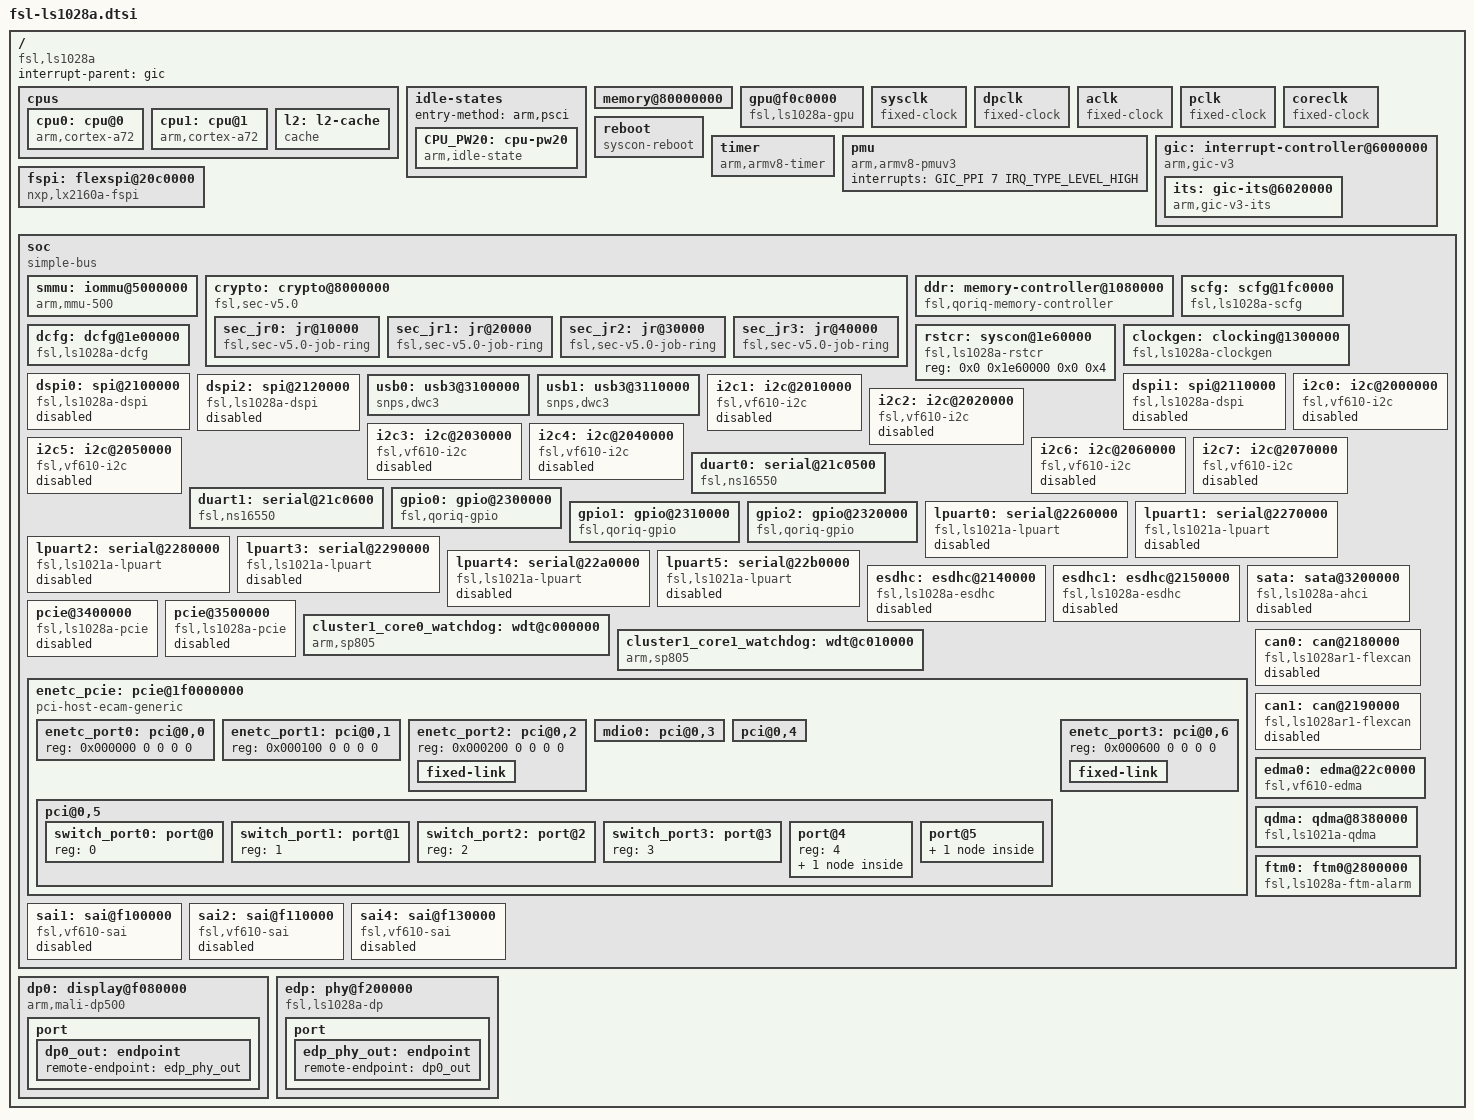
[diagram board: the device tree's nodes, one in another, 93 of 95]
// SPDX-License-Identifier: (GPL-2.0+ OR MIT)
/*
 * Device Tree Include file for NXP Layerscape-1028A family SoC.
 *
 * Copyright 2017-2019 NXP
 *
 * Harninder Rai <harninder.rai@nxp.com>
 *
 */

#include <dt-bindings/interrupt-controller/arm-gic.h>
#include <dt-bindings/thermal/thermal.h>

/ {
	compatible = "fsl,ls1028a";
	interrupt-parent = <&gic>;
	#address-cells = <2>;
	#size-cells = <2>;

	cpus {
		#address-cells = <1>;
		#size-cells = <0>;

		cpu0: cpu@0 {
			device_type = "cpu";
			compatible = "arm,cortex-a72";
			reg = <0x0>;
			clocks = <&clockgen 1 0>;
			next-level-cache = <&l2>;
			cpu-idle-states = <&CPU_PW20>;
			#cooling-cells = <2>;
		};

		cpu1: cpu@1 {
			device_type = "cpu";
			compatible = "arm,cortex-a72";
			reg = <0x1>;
			clocks = <&clockgen 1 0>;
			next-level-cache = <&l2>;
			cpu-idle-states = <&CPU_PW20>;
		};

		l2: l2-cache {
			compatible = "cache";
		};
	};

	idle-states {
		/*
		 * PSCI node is not added default, U-boot will add missing
		 * parts if it determines to use PSCI.
		 */
		entry-method = "arm,psci";

		CPU_PW20: cpu-pw20 {
			  compatible = "arm,idle-state";
			  idle-state-name = "PW20";
			  arm,psci-suspend-param = <0x0>;
			  entry-latency-us = <2000>;
			  exit-latency-us = <2000>;
			  min-residency-us = <6000>;
		};
	};

	memory@80000000 {
		device_type = "memory";
	};

	gpu@f0c0000 {
		compatible = "fsl,ls1028a-gpu";
		reg = <0x0 0x0f0c0000 0x0 0x10000>,
			<0x0 0x80000000 0x0 0x80000000>,
			<0x0 0x0 0x0 0x3000000>;
		reg-names = "base", "phys_baseaddr",
			"contiguous_mem";
		interrupts = <0 220 0x4>;
	};

	sysclk: sysclk {
		compatible = "fixed-clock";
		#clock-cells = <0>;
		clock-frequency = <100000000>;
		clock-output-names = "sysclk";
	};

	dpclk: dpclk {
		compatible = "fixed-clock";
		#clock-cells = <0>;
		clock-frequency = <27000000>;
		clock-output-names= "dpclk";
	};

	aclk: aclk {
		compatible = "fixed-clock";
		#clock-cells = <0>;
		clock-frequency = <650000000>;
		clock-output-names= "aclk";
	};

	pclk: pclk {
		compatible = "fixed-clock";
		#clock-cells = <0>;
		clock-frequency = <650000000>;
		clock-output-names= "pclk";
	};

	coreclk: coreclk {
		compatible = "fixed-clock";
		#clock-cells = <0>;
		clock-frequency = <162500000>;
		clock-output-names= "coreclk";
	};

	reboot {
		compatible = "syscon-reboot";
		regmap = <&rstcr>;
		offset = <0x0>;
		mask = <0x02>;
	};

	timer {
		compatible = "arm,armv8-timer";
		interrupts = <GIC_PPI 13 (GIC_CPU_MASK_RAW(0xf) |
					  IRQ_TYPE_LEVEL_LOW)>,
			     <GIC_PPI 14 (GIC_CPU_MASK_RAW(0xf) |
					  IRQ_TYPE_LEVEL_LOW)>,
			     <GIC_PPI 11 (GIC_CPU_MASK_RAW(0xf) |
					  IRQ_TYPE_LEVEL_LOW)>,
			     <GIC_PPI 10 (GIC_CPU_MASK_RAW(0xf) |
					  IRQ_TYPE_LEVEL_LOW)>;
	};


	pmu {
		compatible = "arm,armv8-pmuv3";
		interrupts = <GIC_PPI 7 IRQ_TYPE_LEVEL_HIGH>;
	};

	gic: interrupt-controller@6000000 {
		compatible= "arm,gic-v3";
		#address-cells = <2>;
		#size-cells = <2>;
		ranges;
		reg= <0x0 0x06000000 0 0x10000>, /* GIC Dist */
			<0x0 0x06040000 0 0x40000>; /* GIC Redistributor */
		#interrupt-cells= <3>;
		interrupt-controller;
		interrupts = <GIC_PPI 9 (GIC_CPU_MASK_RAW(0xf) |
					 IRQ_TYPE_LEVEL_LOW)>;
		its:gic-its@6020000 {
			compatible = "arm,gic-v3-its";
			msi-controller;
			reg = <0x0 0x06020000 0 0x20000>;/* GIC Translater */
		};
	};

	fspi: flexspi@20c0000 {
		compatible = "nxp,lx2160a-fspi", "simple-bus";
		#address-cells = <1>;
		#size-cells = <0>;
		reg = <0x0 0x20c0000 0x0 0x10000>,
		    <0x0 0x20000000 0x0 0x10000000>;
		reg-names = "FSPI", "FSPI-memory";
		interrupts = <0 25 0x4>; /* Level high type */
		clocks = <&clockgen 4 3>, <&clockgen 4 3>;
		clock-names = "fspi_en", "fspi";
	};

	soc: soc {
		compatible = "simple-bus";
		#address-cells = <2>;
		#size-cells = <2>;
		ranges;

		smmu: iommu@5000000 {
			compatible = "arm,mmu-500";
			reg = <0 0x5000000 0 0x800000>;
			#global-interrupts = <8>;
			#iommu-cells = <1>;
			stream-match-mask = <0x7C00>;
			interrupts = <0 13 4>, /* global secure fault */
				     <0 14 4>, /* combined secure interrupt */
				     <0 15 4>, /* global non-secure fault */
				     <0 16 4>, /* combined non-secure interrupt */
				/* performance counter interrupts 0-7 */
				     <0 211 4>, <0 212 4>,
				     <0 213 4>, <0 214 4>,
				/* per context interrupt, 64 interrupts */
				     <0 146 4>, <0 147 4>,
				     <0 148 4>, <0 149 4>,
				     <0 150 4>, <0 151 4>,
				     <0 152 4>, <0 153 4>,
				     <0 154 4>, <0 155 4>,
				     <0 156 4>, <0 157 4>,
				     <0 158 4>, <0 159 4>,
				     <0 160 4>, <0 161 4>,
				     <0 162 4>, <0 163 4>,
				     <0 164 4>, <0 165 4>,
				     <0 166 4>, <0 167 4>,
				     <0 168 4>, <0 169 4>,
				     <0 170 4>, <0 171 4>,
				     <0 172 4>, <0 173 4>,
				     <0 174 4>, <0 175 4>,
				     <0 176 4>, <0 177 4>,
				     <0 178 4>, <0 179 4>,
				     <0 180 4>, <0 181 4>,
				     <0 182 4>, <0 183 4>,
				     <0 184 4>, <0 185 4>,
				     <0 186 4>, <0 187 4>,
				     <0 188 4>, <0 189 4>,
				     <0 190 4>, <0 191 4>,
				     <0 192 4>, <0 193 4>,
				     <0 194 4>, <0 195 4>,
				     <0 196 4>, <0 197 4>,
				     <0 198 4>, <0 199 4>,
				     <0 200 4>, <0 201 4>,
				     <0 202 4>, <0 203 4>,
				     <0 204 4>, <0 205 4>,
				     <0 206 4>, <0 207 4>,
				     <0 208 4>, <0 209 4>;
		};

		crypto: crypto@8000000 {
			compatible = "fsl,sec-v5.0", "fsl,sec-v4.0";
			fsl,sec-era = <10>;
			#address-cells = <1>;
			#size-cells = <1>;
			ranges = <0x0 0x00 0x8000000 0x100000>;
			reg = <0x00 0x8000000 0x0 0x100000>;
			interrupts = <GIC_SPI 139 IRQ_TYPE_LEVEL_HIGH>;
			dma-coherent;

			sec_jr0: jr@10000 {
				compatible = "fsl,sec-v5.0-job-ring",
					     "fsl,sec-v4.0-job-ring";
				reg	= <0x10000 0x10000>;
				interrupts = <GIC_SPI 140 IRQ_TYPE_LEVEL_HIGH>;
				iommus = <&smmu 3>;
			};

			sec_jr1: jr@20000 {
				compatible = "fsl,sec-v5.0-job-ring",
					     "fsl,sec-v4.0-job-ring";
				reg	= <0x20000 0x10000>;
				interrupts = <GIC_SPI 141 IRQ_TYPE_LEVEL_HIGH>;
				iommus = <&smmu 4>;
			};

			sec_jr2: jr@30000 {
				compatible = "fsl,sec-v5.0-job-ring",
					     "fsl,sec-v4.0-job-ring";
				reg	= <0x30000 0x10000>;
				interrupts = <GIC_SPI 142 IRQ_TYPE_LEVEL_HIGH>;
				iommus = <&smmu 5>;
			};

			sec_jr3: jr@40000 {
				compatible = "fsl,sec-v5.0-job-ring",
					     "fsl,sec-v4.0-job-ring";
				reg	= <0x40000 0x10000>;
				interrupts = <GIC_SPI 143 IRQ_TYPE_LEVEL_HIGH>;
				iommus = <&smmu 6>;
			};
		};

		ddr: memory-controller@1080000 {
			compatible = "fsl,qoriq-memory-controller";
			reg = <0x0 0x1080000 0x0 0x1000>;
			interrupts = <GIC_SPI 17 IRQ_TYPE_LEVEL_HIGH>;
			little-endian;
		};

		scfg: scfg@1fc0000 {
			compatible = "fsl,ls1028a-scfg", "syscon";
			reg = <0x0 0x1fc0000 0x0 0x10000>;
			big-endian;
		};

		dcfg: dcfg@1e00000 {
			compatible = "fsl,ls1028a-dcfg", "syscon";
			reg = <0x0 0x1e00000 0x0 0x10000>;
			big-endian;
		};

		rstcr: syscon@1e60000 {
		compatible = "fsl,ls1028a-rstcr", "syscon";
		reg = <0x0 0x1e60000 0x0 0x4>;
		};

		clockgen: clocking@1300000 {
			compatible = "fsl,ls1028a-clockgen";
			reg = <0x0 0x1300000 0x0 0xa0000>;
			#clock-cells = <2>;
			clocks = <&sysclk>;
		};

		dspi0: spi@2100000 {
			compatible = "fsl,ls1028a-dspi", "fsl,ls1021a-v1.0-dspi";
			#address-cells = <1>;
			#size-cells = <0>;
			reg = <0x0 0x2100000 0x0 0x10000>;
			interrupts = <GIC_SPI 26 IRQ_TYPE_LEVEL_HIGH>;
			clock-names = "dspi";
			clocks = <&clockgen 4 1>;
			spi-num-chipselects = <5>;
			little-endian;
			status = "disabled";
		};

		dspi1: spi@2110000 {
			compatible = "fsl,ls1028a-dspi", "fsl,ls1021a-v1.0-dspi";
			#address-cells = <1>;
			#size-cells = <0>;
			reg = <0x0 0x2110000 0x0 0x10000>;
			interrupts = <GIC_SPI 26 IRQ_TYPE_LEVEL_HIGH>;
			clock-names = "dspi";
			clocks = <&clockgen 4 1>;
			spi-num-chipselects = <5>;
			little-endian;
			status = "disabled";
		};

		dspi2: spi@2120000 {
			compatible = "fsl,ls1028a-dspi", "fsl,ls1021a-v1.0-dspi";
			#address-cells = <1>;
			#size-cells = <0>;
			reg = <0x0 0x2120000 0x0 0x10000>;
			interrupts = <GIC_SPI 26 IRQ_TYPE_LEVEL_HIGH>;
			clock-names = "dspi";
			clocks = <&clockgen 4 1>;
			spi-num-chipselects = <5>;
			little-endian;
			status = "disabled";
		};

		usb0:usb3@3100000 {
			compatible= "snps,dwc3";
			reg= <0x0 0x3100000 0x0 0x10000>;
			interrupts= <0 80 0x4>;
			dr_mode= "host";
			snps,dis_rxdet_inp3_quirk;
			snps,quirk-frame-length-adjustment = <0x20>;
			snps,incr-burst-type-adjustment = <1>, <4>, <8>, <16>;
			usb3-lpm-capable;
			snps,dis-u1u2-when-u3-quirk;
			snps,host-vbus-glitches;
		};

		usb1:usb3@3110000 {
			compatible= "snps,dwc3";
			reg= <0x0 0x3110000 0x0 0x10000>;
			interrupts= <0 81 0x4>;
			dr_mode= "host";
			snps,dis_rxdet_inp3_quirk;
			snps,quirk-frame-length-adjustment = <0x20>;
			snps,incr-burst-type-adjustment = <1>, <4>, <8>, <16>;
			usb3-lpm-capable;
			snps,dis-u1u2-when-u3-quirk;
			snps,host-vbus-glitches;
		};

		i2c0: i2c@2000000 {
			compatible = "fsl,vf610-i2c";
			#address-cells = <1>;
			#size-cells = <0>;
			reg = <0x0 0x2000000 0x0 0x10000>;
			interrupts = <GIC_SPI 34 IRQ_TYPE_LEVEL_HIGH>;
			clocks = <&clockgen 4 1>;
			dma-names = "tx", "rx";
			status = "disabled";
		};

		i2c1: i2c@2010000 {
			compatible = "fsl,vf610-i2c";
			#address-cells = <1>;
			#size-cells = <0>;
			reg = <0x0 0x2010000 0x0 0x10000>;
			interrupts = <GIC_SPI 34 IRQ_TYPE_LEVEL_HIGH>;
			clocks = <&clockgen 4 1>;
			status = "disabled";
		};

		i2c2: i2c@2020000 {
			compatible = "fsl,vf610-i2c";
			#address-cells = <1>;
			#size-cells = <0>;
			reg = <0x0 0x2020000 0x0 0x10000>;
			interrupts = <GIC_SPI 35 IRQ_TYPE_LEVEL_HIGH>;
			clocks = <&clockgen 4 1>;
			status = "disabled";
		};

		i2c3: i2c@2030000 {
			compatible = "fsl,vf610-i2c";
			#address-cells = <1>;
			#size-cells = <0>;
			reg = <0x0 0x2030000 0x0 0x10000>;
			interrupts = <GIC_SPI 35 IRQ_TYPE_LEVEL_HIGH>;
			clocks = <&clockgen 4 1>;
			status = "disabled";
		};

		i2c4: i2c@2040000 {
			compatible = "fsl,vf610-i2c";
			#address-cells = <1>;
			#size-cells = <0>;
			reg = <0x0 0x2040000 0x0 0x10000>;
			interrupts = <GIC_SPI 74 IRQ_TYPE_LEVEL_HIGH>;
			clocks = <&clockgen 4 1>;
			status = "disabled";
		};

		i2c5: i2c@2050000 {
			compatible = "fsl,vf610-i2c";
			#address-cells = <1>;
			#size-cells = <0>;
			reg = <0x0 0x2050000 0x0 0x10000>;
			interrupts = <GIC_SPI 74 IRQ_TYPE_LEVEL_HIGH>;
			clocks = <&clockgen 4 1>;
			status = "disabled";
		};

		i2c6: i2c@2060000 {
			compatible = "fsl,vf610-i2c";
			#address-cells = <1>;
			#size-cells = <0>;
			reg = <0x0 0x2060000 0x0 0x10000>;
			interrupts = <GIC_SPI 75 IRQ_TYPE_LEVEL_HIGH>;
			clocks = <&clockgen 4 1>;
			status = "disabled";
		};

		i2c7: i2c@2070000 {
			compatible = "fsl,vf610-i2c";
			#address-cells = <1>;
			#size-cells = <0>;
			reg = <0x0 0x2070000 0x0 0x10000>;
			interrupts = <GIC_SPI 75 IRQ_TYPE_LEVEL_HIGH>;
			clocks = <&clockgen 4 1>;
			status = "disabled";
		};

		duart0: serial@21c0500 {
			compatible = "fsl,ns16550", "ns16550a";
			reg = <0x00 0x21c0500 0x0 0x100>;
			interrupts = <GIC_SPI 32 IRQ_TYPE_LEVEL_HIGH>;
			clocks = <&clockgen 4 1>;
		};

		duart1: serial@21c0600 {
			compatible = "fsl,ns16550", "ns16550a";
			reg = <0x00 0x21c0600 0x0 0x100>;
			interrupts = <GIC_SPI 32 IRQ_TYPE_LEVEL_HIGH>;
			clocks = <&clockgen 4 1>;
		};

		gpio0: gpio@2300000 {
			compatible = "fsl,qoriq-gpio";
			reg = <0x0 0x2300000 0x0 0x10000>;
			interrupts = <GIC_SPI 36 IRQ_TYPE_LEVEL_HIGH>;
			gpio-controller;
			#gpio-cells = <2>;
			interrupt-controller;
			#interrupt-cells = <2>;
		};

		gpio1: gpio@2310000 {
			compatible = "fsl,qoriq-gpio";
			reg = <0x0 0x2310000 0x0 0x10000>;
			interrupts = <GIC_SPI 36 IRQ_TYPE_LEVEL_HIGH>;
			gpio-controller;
			#gpio-cells = <2>;
			interrupt-controller;
			#interrupt-cells = <2>;
		};

		gpio2: gpio@2320000 {
			compatible = "fsl,qoriq-gpio";
			reg = <0x0 0x2320000 0x0 0x10000>;
			interrupts = <GIC_SPI 37 IRQ_TYPE_LEVEL_HIGH>;
			gpio-controller;
			#gpio-cells = <2>;
			interrupt-controller;
			#interrupt-cells = <2>;
		};

		lpuart0: serial@2260000 {
			compatible = "fsl,ls1021a-lpuart";
			reg = <0x0 0x2260000 0x0 0x1000>;
			interrupts = <GIC_SPI 232 IRQ_TYPE_LEVEL_HIGH>;
			clocks = <&clockgen 4 1>;
			clock-names = "ipg";
			little-endian;
			status = "disabled";
		};

		lpuart1: serial@2270000 {
			compatible = "fsl,ls1021a-lpuart";
			reg = <0x0 0x2270000 0x0 0x1000>;
			interrupts = <GIC_SPI 233 IRQ_TYPE_LEVEL_HIGH>;
			clocks = <&clockgen 4 1>;
			clock-names = "ipg";
			little-endian;
			status = "disabled";
		};

		lpuart2: serial@2280000 {
			compatible = "fsl,ls1021a-lpuart";
			reg = <0x0 0x2280000 0x0 0x1000>;
			interrupts = <GIC_SPI 234 IRQ_TYPE_LEVEL_HIGH>;
			clocks = <&clockgen 4 1>;
			clock-names = "ipg";
			little-endian;
			status = "disabled";
		};

		lpuart3: serial@2290000 {
			compatible = "fsl,ls1021a-lpuart";
			reg = <0x0 0x2290000 0x0 0x1000>;
			interrupts = <GIC_SPI 235 IRQ_TYPE_LEVEL_HIGH>;
			clocks = <&clockgen 4 1>;
			clock-names = "ipg";
			little-endian;
			status = "disabled";
		};

		lpuart4: serial@22a0000 {
			compatible = "fsl,ls1021a-lpuart";
			reg = <0x0 0x22a0000 0x0 0x1000>;
			interrupts = <GIC_SPI 236 IRQ_TYPE_LEVEL_HIGH>;
			clocks = <&clockgen 4 1>;
			clock-names = "ipg";
			little-endian;
			status = "disabled";
		};

		lpuart5: serial@22b0000 {
			compatible = "fsl,ls1021a-lpuart";
			reg = <0x0 0x22b0000 0x0 0x1000>;
			interrupts = <GIC_SPI 237 IRQ_TYPE_LEVEL_HIGH>;
			clocks = <&clockgen 4 1>;
			clock-names = "ipg";
			little-endian;
			status = "disabled";
		};

		esdhc: esdhc@2140000 {
			compatible = "fsl,ls1028a-esdhc", "fsl,esdhc";
			reg = <0x0 0x2140000 0x0 0x10000>;
			interrupts = <0 28 0x4>; /* Level high type */
			clock-frequency = <0>;
			clocks = <&clockgen 2 1>;
			voltage-ranges = <1800 1800 3300 3300>;
			sdhci,auto-cmd12;
			little-endian;
			bus-width = <4>;
			status = "disabled";
		};

		esdhc1: esdhc@2150000 {
			compatible = "fsl,ls1028a-esdhc", "fsl,esdhc";
			reg = <0x0 0x2150000 0x0 0x10000>;
			interrupts = <0 63 0x4>; /* Level high type */
			clock-frequency = <0>;
			clocks = <&clockgen 2 1>;
			voltage-ranges = <1800 1800 3300 3300>;
			sdhci,auto-cmd12;
			broken-cd;
			little-endian;
			bus-width = <4>;
			status = "disabled";
		};

		sata: sata@3200000 {
			compatible = "fsl,ls1028a-ahci";
			reg = <0x0 0x3200000 0x0 0x10000>,
				<0x7 0x100520 0x0 0x4>;
			reg-names = "ahci", "sata-ecc";
			interrupts = <GIC_SPI 133 IRQ_TYPE_LEVEL_HIGH>;
			clocks = <&clockgen 4 1>;
			status = "disabled";
		};

		pcie@3400000 {
			compatible = "fsl,ls1028a-pcie", "snps,dw-pcie";
			reg = <0x00 0x03400000 0x0 0x00100000   /* controller registers */
			       0x80 0x00000000 0x0 0x00002000>; /* configuration space */
			reg-names = "regs", "config";
			interrupts = <GIC_SPI 108 IRQ_TYPE_LEVEL_HIGH>, /* PME interrupt */
				     <GIC_SPI 109 IRQ_TYPE_LEVEL_HIGH>; /* aer interrupt */
			interrupt-names = "pme", "aer";
			#address-cells = <3>;
			#size-cells = <2>;
			device_type = "pci";
			dma-coherent;
			num-lanes = <4>;
			bus-range = <0x0 0xff>;
			ranges = <0x81000000 0x0 0x00000000 0x80 0x00010000 0x0 0x00010000   /* downstream I/O */
				  0x82000000 0x0 0x40000000 0x80 0x40000000 0x0 0x40000000>; /* non-prefetchable memory */
			msi-parent = <&its>;
			#interrupt-cells = <1>;
			interrupt-map-mask = <0 0 0 7>;
			interrupt-map = <0000 0 0 1 &gic GIC_SPI 109 IRQ_TYPE_LEVEL_HIGH>,
					<0000 0 0 2 &gic GIC_SPI 110 IRQ_TYPE_LEVEL_HIGH>,
					<0000 0 0 3 &gic GIC_SPI 111 IRQ_TYPE_LEVEL_HIGH>,
					<0000 0 0 4 &gic GIC_SPI 112 IRQ_TYPE_LEVEL_HIGH>;
			status = "disabled";
		};

		pcie@3500000 {
			compatible = "fsl,ls1028a-pcie", "snps,dw-pcie";
			reg = <0x00 0x03500000 0x0 0x00100000   /* controller registers */
			       0x88 0x00000000 0x0 0x00002000>; /* configuration space */
			reg-names = "regs", "config";
			interrupts = <GIC_SPI 113 IRQ_TYPE_LEVEL_HIGH>,
				     <GIC_SPI 114 IRQ_TYPE_LEVEL_HIGH>;
			interrupt-names = "pme", "aer";
			#address-cells = <3>;
			#size-cells = <2>;
			device_type = "pci";
			dma-coherent;
			num-lanes = <4>;
			bus-range = <0x0 0xff>;
			ranges = <0x81000000 0x0 0x00000000 0x88 0x00010000 0x0 0x00010000   /* downstream I/O */
				  0x82000000 0x0 0x40000000 0x88 0x40000000 0x0 0x40000000>; /* non-prefetchable memory */
			msi-parent = <&its>;
			#interrupt-cells = <1>;
			interrupt-map-mask = <0 0 0 7>;
			interrupt-map = <0000 0 0 1 &gic GIC_SPI 114 IRQ_TYPE_LEVEL_HIGH>,
					<0000 0 0 2 &gic GIC_SPI 115 IRQ_TYPE_LEVEL_HIGH>,
					<0000 0 0 3 &gic GIC_SPI 116 IRQ_TYPE_LEVEL_HIGH>,
					<0000 0 0 4 &gic GIC_SPI 117 IRQ_TYPE_LEVEL_HIGH>;
			status = "disabled";
		};

		cluster1_core0_watchdog: wdt@c000000 {
			compatible = "arm,sp805", "arm,primecell";
			reg = <0x0 0xc000000 0x0 0x1000>;
			clocks = <&clockgen 4 15>, <&clockgen 4 15>;
			clock-names = "apb_pclk", "wdog_clk";
		};

		cluster1_core1_watchdog: wdt@c010000 {
			compatible = "arm,sp805", "arm,primecell";
			reg = <0x0 0xc010000 0x0 0x1000>;
			clocks = <&clockgen 4 15>, <&clockgen 4 15>;
			clock-names = "apb_pclk", "wdog_clk";
		};

		enetc_pcie: pcie@1f0000000 { /* rcie_enetc */
			compatible = "pci-host-ecam-generic";
			reg = <0x01 0xf0000000 0x0 0x100000>;
			#address-cells = <3>;
			#size-cells = <2>;
			msi-parent = <&its>;
			device_type = "pci";
			bus-range = <0x0 0x0>;
			dma-coherent;
			msi-map = <0 &its 0x17 0xe>;
			iommu-map = <0 &smmu 0x17 0xe>;
			ranges = <0x82000000 0x0 0x00000000  0x1 0xf8000000  0x0 0x160000   /* PF0-6 BAR0 - non-prefetchable memory */
				  0xc2000000 0x0 0x00000000  0x1 0xf8160000  0x0 0x070000   /* PF0-6, BAR2 - prefetchable memory */
				  0x82000000 0x0 0x00000000  0x1 0xf81d0000  0x0 0x020000   /* PF0, VF-BAR0 - non-prefetchable memory */
				  0xc2000000 0x0 0x00000000  0x1 0xf81f0000  0x0 0x020000   /* PF0, VF-BAR2 - prefetchable memory */
				  0x82000000 0x0 0x00000000  0x1 0xf8210000  0x0 0x020000   /* PF1, VF-BAR0 - non-prefetchable memory */
				  0xc2000000 0x0 0x00000000  0x1 0xf8230000  0x0 0x020000   /* PF1, VF-BAR1 - prefetchable memory */
				  0x82000000 0x0 0x00000000  0x1 0xfc000000  0x0 0x400000>; /* PF2/PF5, BAR4 - non-prefetchable memory */

			enetc_port0: pci@0,0 {
				reg = <0x000000 0 0 0 0>;
			};
			enetc_port1: pci@0,1 {
				reg = <0x000100 0 0 0 0>;
			};
			enetc_port2: pci@0,2 {
				reg = <0x000200 0 0 0 0>;
				fixed-link {
					speed = <1000>;
					full-duplex;
				};
			};
			mdio0: pci@0,3 {
				reg = <0x000300 0 0 0 0>;
				device_type = "mdio";
				#address-cells = <1>;
				#size-cells = <0>;
				little-endian;
			};
			pci@0,4 {
				reg = <0x000400 0 0 0 0>;
				clocks = <&clockgen 4 0>;
				little-endian;
			};
			pci@0,5 {
				reg = <0x000500 0 0 0 0>;
				/* l2switch ports */
				#address-cells = <1>;
				#size-cells = <0>;
				/* IEP INT_B */
				interrupts = <GIC_SPI 95 IRQ_TYPE_LEVEL_HIGH>;

				/* external ports */
				switch_port0: port@0 {
					reg = <0>;
				};
				switch_port1: port@1 {
					reg = <1>;
				};
				switch_port2: port@2 {
					reg = <2>;
				};
				switch_port3: port@3 {
					reg = <3>;
				};
				/* internal to-cpu ports */
				port@4 {
					reg = <4>;
					fixed-link {
						speed = <1000>;
						full-duplex;
					};
				};
				port@5 {
					reg = <5>;
					cpu-ethernet = <&enetc_port3>;
					fixed-link {
						speed = <1000>;
						full-duplex;
					};
				};

			};
			enetc_port3: pci@0,6 {
				reg = <0x000600 0 0 0 0>;
				fixed-link {
					speed = <1000>;
					full-duplex;
				};
			};
		};

		can0: can@2180000 {
			compatible = "fsl,ls1028ar1-flexcan", "fsl,lx2160ar1-flexcan";
			reg = <0x0 0x2180000 0x0 0x10000>;
			interrupts = <GIC_SPI 21 IRQ_TYPE_LEVEL_HIGH>;
			clocks = <&clockgen 4 1>, <&clockgen 4 1>;
			clock-names = "ipg", "per";
			status = "disabled";
		};

		can1: can@2190000 {
			compatible = "fsl,ls1028ar1-flexcan", "fsl,lx2160ar1-flexcan";
			reg = <0x0 0x2190000 0x0 0x10000>;
			interrupts = <GIC_SPI 22 IRQ_TYPE_LEVEL_HIGH>;
			clocks = <&clockgen 4 1>, <&clockgen 4 1>;
			clock-names = "ipg", "per";
			status = "disabled";
		};

		edma0: edma@22c0000 {
			#dma-cells = <2>;
			compatible = "fsl,vf610-edma";
			reg = <0x0 0x22c0000 0x0 0x10000>,
			      <0x0 0x22d0000 0x0 0x10000>,
			      <0x0 0x22e0000 0x0 0x10000>;
			interrupts = <0 56 0x4>,
				     <0 56 0x4>;
			interrupt-names = "edma-tx", "edma-err";
			dma-channels = <32>;
			clock-names = "dmamux0", "dmamux1";
			clocks = <&clockgen 4 1>,
				 <&clockgen 4 1>;
		};

		qdma: qdma@8380000 {
			compatible = "fsl,ls1021a-qdma", "fsl,ls1028a-qdma";
			reg = <0x0 0x8380000 0x0 0x1000>, /* Controller regs */
			      <0x0 0x8390000 0x0 0x10000>, /* Status regs */
			      <0x0 0x83a0000 0x0 0x40000>; /* Block regs */
			interrupts = <0 43 0x4>,
				     <0 251 0x4>,
				     <0 252 0x4>,
				     <0 253 0x4>,
				     <0 254 0x4>;
			interrupt-names = "qdma-error", "qdma-queue0",
				"qdma-queue1", "qdma-queue2", "qdma-queue3";
			channels = <8>;
			block-number = <1>;
			block-offset = <0x10000>;
			queues = <2>;
			status-sizes = <64>;
			queue-sizes = <64 64>;
		};

		ftm0: ftm0@2800000 {
			compatible = "fsl,ls1028a-ftm-alarm";
			reg = <0x0 0x2800000 0x0 0x10000>,
			      <0x0 0x1e34050 0x0 0x4>;
			reg-names = "ftm", "pmctrl";
			interrupts = <GIC_SPI 44 IRQ_TYPE_LEVEL_HIGH>;
			status = "okay";
		};

		sai1: sai@f100000 {
			#sound-dai-cells = <0>;
			compatible = "fsl,vf610-sai";
			reg = <0x0 0xf100000 0x0 0x10000>;
			interrupts = <0 82 0x4>;
			clocks = <&clockgen 4 1>, <&clockgen 4 1>,
				 <&clockgen 4 1>, <&clockgen 4 1>;
			clock-names = "bus", "mclk1", "mclk2", "mclk3";
			dma-names = "tx", "rx";
			dmas = <&edma0 1 4>,
			       <&edma0 1 3>;
			status = "disabled";
		};

		sai2: sai@f110000 {
			#sound-dai-cells = <0>;
			compatible = "fsl,vf610-sai";
			reg = <0x0 0xf110000 0x0 0x10000>;
			interrupts = <0 82 0x4>;
			clocks = <&clockgen 4 1>, <&clockgen 4 1>,
				 <&clockgen 4 1>, <&clockgen 4 1>;
			clock-names = "bus", "mclk1", "mclk2", "mclk3";
			dma-names = "tx", "rx";
			dmas = <&edma0 1 6>,
			       <&edma0 1 5>;
			status = "disabled";
		};

		sai4: sai@f130000 {
			#sound-dai-cells = <0>;
			compatible = "fsl,vf610-sai";
			reg = <0x0 0xf130000 0x0 0x10000>;
			interrupts = <0 83 0x4>;
			clocks = <&clockgen 4 1>, <&clockgen 4 1>,
				 <&clockgen 4 1>, <&clockgen 4 1>;
			clock-names = "bus", "mclk1", "mclk2", "mclk3";
			dma-names = "tx", "rx";
			dmas = <&edma0 1 10>,
			       <&edma0 1 9>;
			status = "disabled";
		};
	};

	dp0: display@f080000 {
		compatible = "arm,mali-dp500";
		reg = <0x0 0xf080000 0x0 0x10000>;
		interrupts = <0 222 0x4>,
			     <0 223 0x4>;
		interrupt-names = "DE", "SE";
		clocks = <&dpclk>, <&aclk>,
			 <&aclk>, <&pclk>;
		clock-names = "pxlclk", "mclk", "aclk", "pclk";
		arm,malidp-output-port-lines = /bits/ 8 <8 8 8>;

		port {
			dp0_out: endpoint {
				remote-endpoint = <&edp_phy_out>;
			};
		};
	};

	edp: phy@f200000 {
		compatible = "fsl,ls1028a-dp";
		reg = <0x0 0xf1f0000 0x0 0xffff>, /* Multimedia PLL Register */
		    <0x0 0xf200000 0x0 0xfffff>; /* HDP Register*/
		interrupts = <0 221 0x4>;
		clocks = <&coreclk>,
			 <&coreclk>,
			 <&coreclk>,
			 <&coreclk>,
			 <&dpclk>,
			 <&dpclk>,
			 <&dpclk>,
			 <&coreclk>,
			 <&coreclk>,
			 <&coreclk>,
			 <&coreclk>,
			 <&coreclk>,
			 <&coreclk>,
			 <&coreclk>,
			 <&coreclk>,
			 <&dpclk>,
			 <&coreclk>,
			 <&coreclk>;
		clock-names = "dig_pll", "av_pll", "clk_ipg",
			      "clk_core", "clk_pxl", "clk_pxl_mux",
			      "clk_pxl_link", "clk_hdp", "clk_phy",
			      "clk_apb", "clk_lis","clk_msi",
			      "clk_lpcg", "clk_even","clk_dbl",
			      "clk_vif", "clk_apb_csr","clk_apb_ctrl";

		port {
			edp_phy_out: endpoint {
				remote-endpoint = <&dp0_out>;
			};
		};
	};
};

